# CY8C4xxx register map
File version: 0.1
Registers are 8-bit, read-write, no defined reset value unless marked. A register's access mark holds for its fields unless they carry their own. Offsets are from the block's base; [hi:lo] are bit positions; {n}, {i} and the like mark numbered series.

## TCPWM — Quad Timer/Counter/PWM
Base 0x40050000
0x00 CTRL 32-bit — TCPWM control register 0.
  [7:0] COUNTER_ENABLED — Counter enables for counters 0 up to CNT_NR-1. When '0': counter disabled. When '1': counter enabled. Counter control information should only be modified when the counter is disabled. When a counter is disabled, the associated counter triggers in the MMIO CMD register are set to '0'.
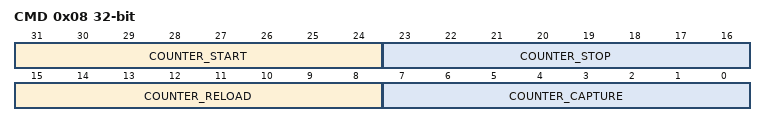
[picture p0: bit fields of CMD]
0x08 CMD 32-bit — TCPWM command register.
  [31:24] COUNTER_START write-once — Counters SW start trigger. For HW behavior, see COUNTER_CAPTURE field.
  [23:16] COUNTER_STOP write-once — Counters SW stop trigger. For HW behavior, see COUNTER_CAPTURE field.
  [15:8] COUNTER_RELOAD write-once — Counters SW reload trigger. For HW behavior, see COUNTER_CAPTURE field.
  [7:0] COUNTER_CAPTURE write-once — Counters SW capture trigger. When written with '1', a capture trigger is generated and the HW sets the field to '0' when the SW trigger has taken effect. It should be noted that the HW operates on the counter frequency. If the counter is disabled through CTRL.COUNTER_ENABLED, the field is immediately set to '0'.
0x0C INTR_CAUSE 32-bit — TCPWM Counter interrupt cause register.
  [7:0] COUNTER_INT ro — Counters interrupt signal active.

## LCD — LCD Controller Block
Base 0x40090000
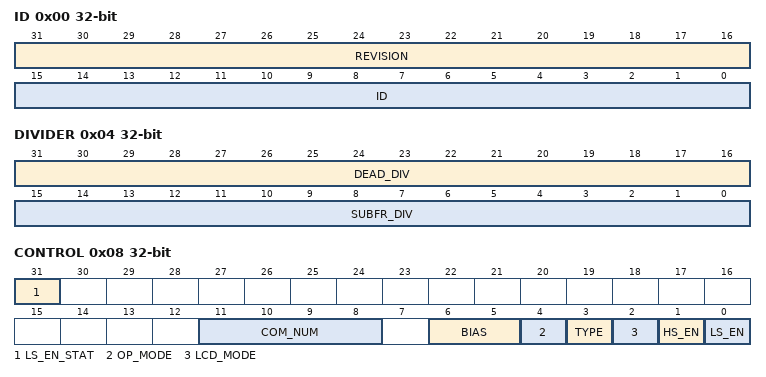
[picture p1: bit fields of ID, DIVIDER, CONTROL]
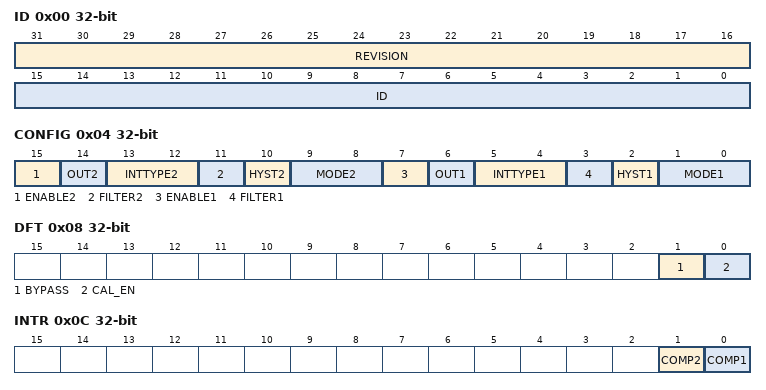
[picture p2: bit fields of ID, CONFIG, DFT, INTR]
0x00 ID 32-bit — ID & Revision
  [31:16] REVISION ro — the version number is 0x0001
  [15:0] ID ro — the ID of LCD controller peripheral is 0xF0F0
0x04 DIVIDER 32-bit — LCD Divider Register
  [31:16] DEAD_DIV — Length of the dead time period in cycles. When set to zero, no dead time period exists.
  [15:0] SUBFR_DIV — Input clock frequency divide value, to generate the 1/4 sub-frame period. The sub-frame period is 4*(SUBFR_DIV+1) cycles long.
0x08 CONTROL 32-bit — LCD Configuration Register
  [31] LS_EN_STAT ro — LS enable status bit. This bit is a copy of LS_EN that is synchronized to the low speed clock domain and back to the system clock domain. Firmware can use this bit to observe whether LS_EN has taken effect in the low speed clock domain. Firmware should never change the configuration for the LS generator without ensuring this bit is 0.?The following procedure should be followed to disable the LS generator:?1. If LS_EN=0 we are done. Exit the procedure.?2. Check that LS_EN_STAT=1. If not, wait until it is. This will catch the case of a recent enable (LS_EN=1) that has not taken effect yet.?3. Set LS_EN=0.?4. Wait until LS_EN_STAT=0.
  [11:8] COM_NUM — The number of COM connections minus 2. So:?0: 2 COM's?1: 3 COM's?...?13: 15 COM's?14: 16 COM's?15: undefined
  [6:5] BIAS — PWM bias selection
    0=HALF; 1=THIRD; 2=FOURTH; 3=FIFTH
  [4] OP_MODE — Driving mode configuration
    0=PWM; 1=CORRELATION
  [3] TYPE — LCD driving waveform type configuration.
    0=A; 1=B
  [2] LCD_MODE — HS/LS Mode selection
    0=LS; 1=HS
  [1] HS_EN — high speed (LS) generator enable?1: enable?0: disable
  [0] LS_EN — Low speed (HS) generator enable?1: enable?0: disable
{0x100+4i} DATA{i:02} 32-bit (i=0..4) — LCD Pin Data Registers
  [31:0] DATA — Bits [4i+3:4i] represent the pin data for pin [i] for COMS 1-4 (COM1 is lsb).

## LPCOMP — Low Power Comparators
Base 0x400A0000
0x00 ID 32-bit — ID & Revision
  [31:16] REVISION ro — the version number is 0x0001
  [15:0] ID ro — the ID of LPCOMP peripheral is 0xE0E0
0x04 CONFIG 32-bit — LPCOMP Configuration Register
  [15] ENABLE2 — Enable comparator #2
  [14] OUT2 ro — Current output value of the comparator.
  [13:12] INTTYPE2 — Sets which edge will trigger an IRQ
    0=DISABLE; 1=RISING; 2=FALLING; 3=BOTH
  [11] FILTER2 — Enable the inline digital filter for the comparator
  [10] HYST2 — Add 10mV hysteresis to the comparator
  [9:8] MODE2 — Operating mode for the comparator
    0=SLOW; 1=FAST; 2=ULP
  [7] ENABLE1 — Enable comparator #1
  [6] OUT1 ro — Current output value of the comparator.
  [5:4] INTTYPE1 — Sets which edge will trigger an IRQ
    0=DISABLE; 1=RISING; 2=FALLING; 3=BOTH
  [3] FILTER1 — Enable the inline digital filter for the comparator
  [2] HYST1 — Add 10mV hysteresis to the comparator
  [1:0] MODE1 — Operating mode for the comparator
    0=SLOW; 1=FAST; 2=ULP
0x08 DFT 32-bit — LPCOMP DFT register
  [1] BYPASS — Enables bypass of inp input straight to output. This can be used as baseline to measure comparator response time.
  [0] CAL_EN — Calibration enable. Setting this bit will short the inputs of the comparators for offset measurement.
0x0C INTR 32-bit — LPCOMP Interrupt request register
  [1] COMP2 write-once — Comparator #2 generated an interrupt
  [0] COMP1 write-once — Comparator #1 generated an interrupt
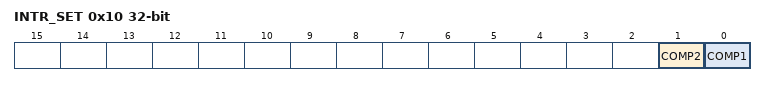
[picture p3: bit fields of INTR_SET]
0x10 INTR_SET 32-bit — LPCOMP Interrupt set register
  [1] COMP2 write-once — Write with '1' to set corresponding bit in interrupt request register.
  [0] COMP1 write-once — Write with '1' to set corresponding bit in interrupt request register.
0xFF00 TRIM1 32-bit — LPCOMP Trim Register
  [4:0] COMP1_TRIMA — Trim A for Comparator #1
0xFF04 TRIM2 32-bit — LPCOMP Trim Register
  [4:0] COMP1_TRIMB — Trim B for Comparator #1
0xFF08 TRIM3 32-bit — LPCOMP Trim Register
  [4:0] COMP2_TRIMA — Trim A for Comparator #2
0xFF0C TRIM4 32-bit — LPCOMP Trim Register
  [4:0] COMP2_TRIMB — Trim B for Comparator #2
